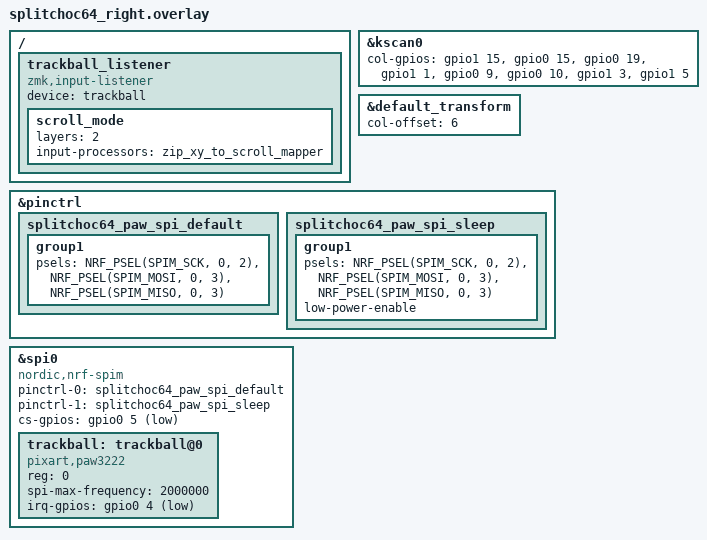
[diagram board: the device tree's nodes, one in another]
#include <zephyr/dt-bindings/pinctrl/nrf-pinctrl.h>
#include <input/processors.dtsi>

#include "splitchoc64.dtsi"

&kscan0 {
    /* RIGHT central: COL0..7 = D10,D11,D12,D13,D14,D15,D17,D18 */
    col-gpios
        = <&gpio1 15 GPIO_ACTIVE_HIGH>
        , <&gpio0 15 GPIO_ACTIVE_HIGH>
        , <&gpio0 19 GPIO_ACTIVE_HIGH>
        , <&gpio1 1 GPIO_ACTIVE_HIGH>
        , <&gpio0 9 GPIO_ACTIVE_HIGH>
        , <&gpio0 10 GPIO_ACTIVE_HIGH>
        , <&gpio1 3 GPIO_ACTIVE_HIGH>
        , <&gpio1 5 GPIO_ACTIVE_HIGH>
        ;
};

&default_transform {
    /* LEFT uses six matrix columns, so RIGHT begins at global column 6. */
    col-offset = <6>;
};

&pinctrl {
    splitchoc64_paw_spi_default: splitchoc64_paw_spi_default {
        group1 {
            psels = <NRF_PSEL(SPIM_SCK, 0, 2)>,
                    <NRF_PSEL(SPIM_MOSI, 0, 3)>,
                    <NRF_PSEL(SPIM_MISO, 0, 3)>;
        };
    };

    splitchoc64_paw_spi_sleep: splitchoc64_paw_spi_sleep {
        group1 {
            psels = <NRF_PSEL(SPIM_SCK, 0, 2)>,
                    <NRF_PSEL(SPIM_MOSI, 0, 3)>,
                    <NRF_PSEL(SPIM_MISO, 0, 3)>;
            low-power-enable;
        };
    };
};

&spi0 {
    status = "okay";
    compatible = "nordic,nrf-spim";
    pinctrl-0 = <&splitchoc64_paw_spi_default>;
    pinctrl-1 = <&splitchoc64_paw_spi_sleep>;
    pinctrl-names = "default", "sleep";
    cs-gpios = <&gpio0 5 GPIO_ACTIVE_LOW>;

    trackball: trackball@0 {
        status = "okay";
        compatible = "pixart,paw3222";
        reg = <0>;
        spi-max-frequency = <2000000>;
        irq-gpios = <&gpio0 4 GPIO_ACTIVE_LOW>;
    };
};

/ {
    trackball_listener: trackball_listener {
        compatible = "zmk,input-listener";
        device = <&trackball>;

        scroll_mode {
            layers = <2>;
            input-processors = <&zip_xy_to_scroll_mapper>;
        };
    };
};
